# ATSAMG54 register map
Vendor: Microchip Technology; Series: SAMG54; File version: 0
CPU: CM4 r0p1, little endian, MPU, FPU, 4 interrupt priority bits
Registers are 32-bit, read-write, reset 0x0 unless marked. A register's access mark holds for its fields unless they carry their own. Offsets are from the block's base; [hi:lo] are bit positions; {n}, {i} and the like mark numbered series.

## EFC — Embedded Flash Controller
Base 0x400E0A00; register names take the prefix EFC_
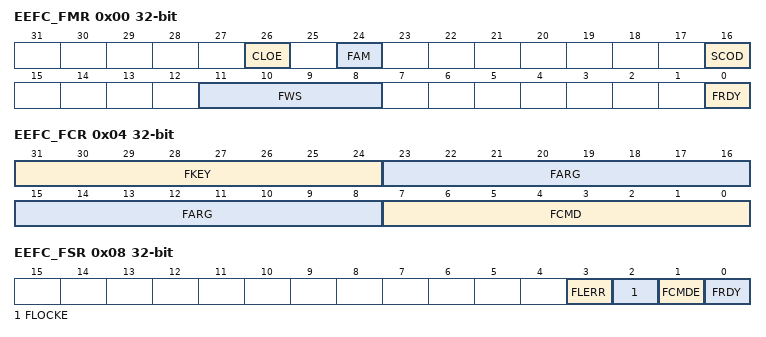
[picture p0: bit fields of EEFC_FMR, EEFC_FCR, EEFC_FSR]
0x00 EEFC_FMR — EEFC Flash Mode Register
  [26] CLOE — Code Loop Optimization Enable
  [24] FAM — Flash Access Mode
  [16] SCOD — Sequential Code Optimization Disable
  [11:8] FWS — Flash Wait State
  [0] FRDY — Flash Ready Interrupt Enable
0x04 EEFC_FCR wo — EEFC Flash Command Register
  [31:24] FKEY — Flash Writing Protection Key
    90=PASSWD (The 0x5A value enables the command defined by the bits of the register. If the field is written with a different value, the write is not performed and no action is started.)
  [23:8] FARG — Flash Command Argument
  [7:0] FCMD — Flash Command
    0=GETD (Get Flash descriptor); 1=WP (Write page); 2=WPL (Write page and lock); 3=EWP (Erase page and write page); 4=EWPL (Erase page and write page then lock); 5=EA (Erase all); 7=EPA (Erase pages); 8=SLB (Set lock bit); 9=CLB (Clear lock bit); 10=GLB (Get lock bit); 11=SGPB (Set GPNVM bit); 12=CGPB (Clear GPNVM bit); 13=GGPB (Get GPNVM bit); 14=STUI (Start read unique identifier); 15=SPUI (Stop read unique identifier); 16=GCALB (Get CALIB bit); 17=ES (Erase sector); 18=WUS (Write user signature); 19=EUS (Erase user signature); 20=STUS (Start read user signature); 21=SPUS (Stop read user signature)
0x08 EEFC_FSR ro — EEFC Flash Status Register
  [3] FLERR — Flash Error Status (cleared when a programming operation starts)
  [2] FLOCKE — Flash Lock Error Status (cleared on read)
  [1] FCMDE — Flash Command Error Status (cleared on read or by writing EEFC_FCR)
  [0] FRDY — Flash Ready Status (cleared when Flash is busy)
0x0C EEFC_FRR ro — EEFC Flash Result Register
  [31:0] FVALUE — Flash Result Value

## GPBR — General Purpose Backup Registers
Base 0x400E1490; register names take the prefix GPBR_
{0x0+4i} SYS_GPBR[{i}] (i=0..7) — General Purpose Backup Register 0
  [31:0] GPBR_VALUE — Value of GPBR x

## MATRIX — AHB Bus Matrix
Base 0x400E0200; register names take the prefix MATRIX_
{0x0+4i} MATRIX_MCFG[{i}] (i=0..2) — Master Configuration Register 0
  [2:0] ULBT — Undefined Length Burst Type
    0=INFINITE (No predicted end of burst is generated and therefore INCR bursts coming from this master cannot be broken.); 1=SINGLE (The undefined length burst is treated as a succession of single access allowing rearbitration at each beat of the INCR burst.); 2=FOUR_BEAT (The undefined length burst is split into a 4-beat bursts allowing rearbitration at each 4-beat burst end.); 3=EIGHT_BEAT (The undefined length burst is split into 8-beat bursts allowing rearbitration at each 8-beat burst end.); 4=SIXTEEN_BEAT (The undefined length burst is split into 16-beat bursts allowing rearbitration at each 16-beat burst end.)
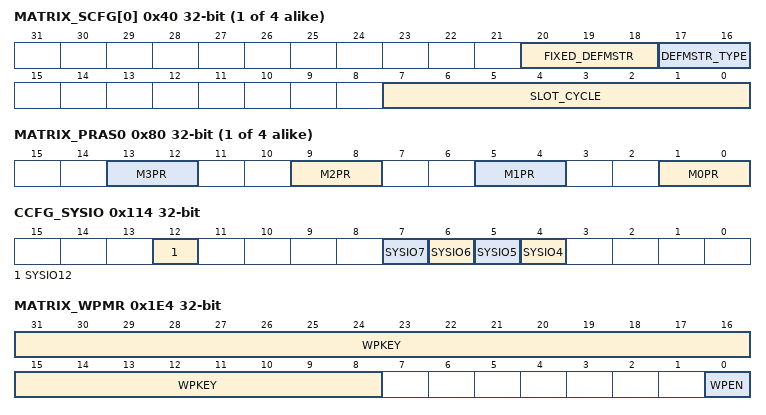
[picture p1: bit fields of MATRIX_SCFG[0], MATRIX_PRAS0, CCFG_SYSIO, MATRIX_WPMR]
{0x40+4i} MATRIX_SCFG[{i}] (i=0..3) — Slave Configuration Register 0
  [20:18] FIXED_DEFMSTR — Fixed Default Master
  [17:16] DEFMSTR_TYPE — Default Master Type
    0=NO_DEFAULT (At the end of current slave access, if no other master request is pending, the slave is disconnected from all masters.This results in having a one cycle latency for the first access of a burst transfer or for a single access.); 1=LAST (At the end of current slave access, if no other master request is pending, the slave stays connected to the last master having accessed it.This results in not having the one cycle latency when the last master tries to access the slave again.); 2=FIXED (At the end of the current slave access, if no other master request is pending, the slave connects to the fixed master the number that has been written in the FIXED_DEFMSTR field.This results in not having the one cycle latency when the fixed master tries to access the slave again.)
  [7:0] SLOT_CYCLE — Maximum Number of Allowed Cycles for a Burst
{0x80+8i} MATRIX_PRAS{i} (i=0..3) — Priority Register A for Slave {i}
  [4n+1:4n] M{n}PR (n=0..3) — Master {n} Priority
0x114 CCFG_SYSIO — System I/O Configuration Register
  [12] SYSIO12 — PB12 or ERASE Assignment
  [7] SYSIO7 — PB7 or TCK/SWCLK Assignment
  [6] SYSIO6 — PB6 or TMS/SWDIO Assignment
  [5] SYSIO5 — PB5 or TDO/TRACESWO Assignment
  [4] SYSIO4 — PB4 or TDI Assignment
0x1E4 MATRIX_WPMR — Write Protection Mode Register
  [31:8] WPKEY — Write Protection Key
    0x4D4154=PASSWD (Writing any other value in this field aborts the write operation of the WPEN bit. Always reads as 0.)
  [0] WPEN — Write Protection Enable
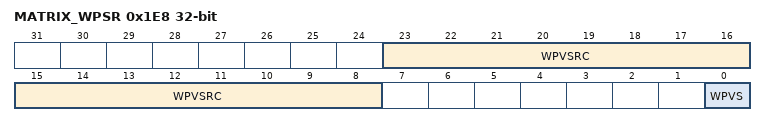
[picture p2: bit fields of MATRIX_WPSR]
0x1E8 MATRIX_WPSR ro — Write Protection Status Register
  [23:8] WPVSRC — Write Protection Violation Source
  [0] WPVS — Write Protection Violation Status
